AUTOSAR XML (schema 4-2-2)
package /ComponentTypes
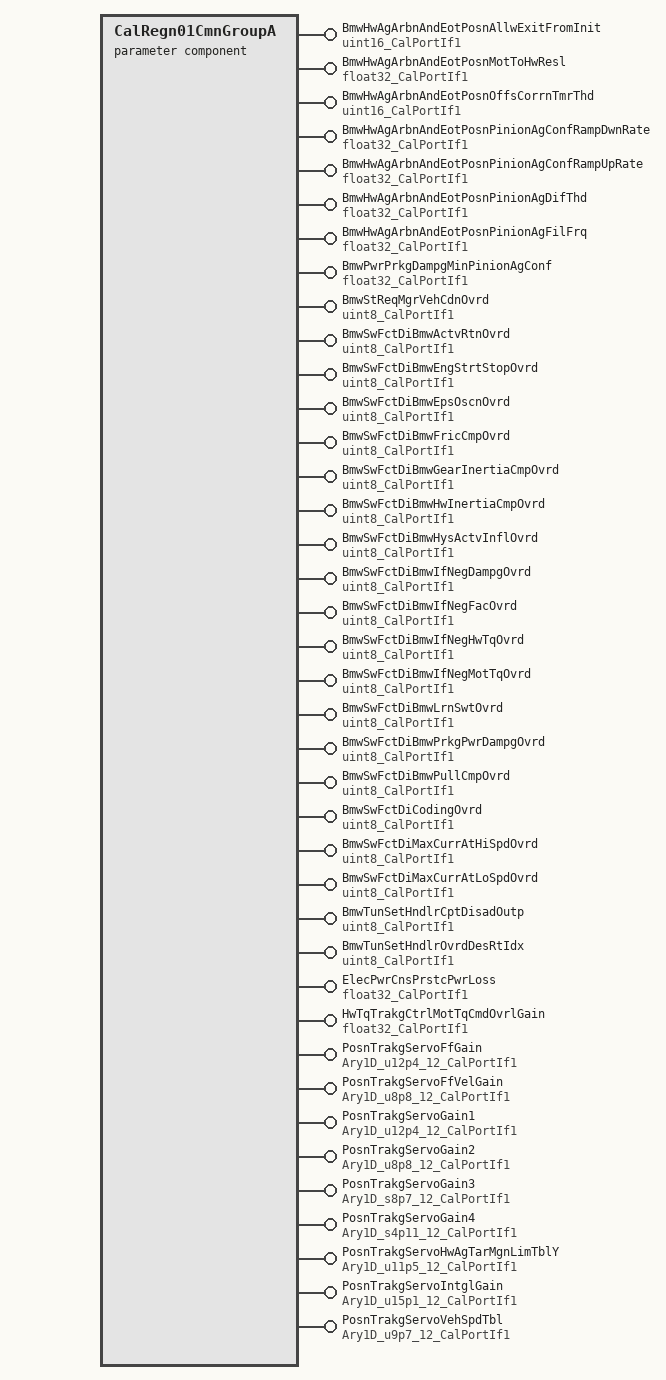
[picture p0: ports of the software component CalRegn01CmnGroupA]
  parameter sw component type CalRegn01CmnGroupA
    39 x provide port:
      BmwHwAgArbnAndEotPosnAllwExitFromInit: parameter-provide-com-spec{init-value=200, parameter=Val}, provided-interface=uint16_CalPortIf1
      BmwHwAgArbnAndEotPosnMotToHwResl: parameter-provide-com-spec{init-value=1, parameter=Val}, provided-interface=float32_CalPortIf1
      BmwHwAgArbnAndEotPosnOffsCorrnTmrThd: parameter-provide-com-spec{init-value=50, parameter=Val}, provided-interface=uint16_CalPortIf1
      BmwHwAgArbnAndEotPosnPinionAgConfRampDwnRate: parameter-provide-com-spec{init-value=1, parameter=Val}, provided-interface=float32_CalPortIf1
      BmwHwAgArbnAndEotPosnPinionAgConfRampUpRate: parameter-provide-com-spec{init-value=0.2, parameter=Val}, provided-interface=float32_CalPortIf1
      BmwHwAgArbnAndEotPosnPinionAgDifThd: parameter-provide-com-spec{init-value=7.5, parameter=Val}, provided-interface=float32_CalPortIf1
      BmwHwAgArbnAndEotPosnPinionAgFilFrq: parameter-provide-com-spec{init-value=10, parameter=Val}, provided-interface=float32_CalPortIf1
      BmwPwrPrkgDampgMinPinionAgConf: parameter-provide-com-spec{init-value=1, parameter=Val}, provided-interface=float32_CalPortIf1
      BmwStReqMgrVehCdnOvrd: parameter-provide-com-spec{init-value=15, parameter=Val}, provided-interface=uint8_CalPortIf1
      BmwSwFctDiBmwActvRtnOvrd: parameter-provide-com-spec{init-value=255, parameter=Val}, provided-interface=uint8_CalPortIf1
      BmwSwFctDiBmwEngStrtStopOvrd: parameter-provide-com-spec{init-value=255, parameter=Val}, provided-interface=uint8_CalPortIf1
      BmwSwFctDiBmwEpsOscnOvrd: parameter-provide-com-spec{init-value=255, parameter=Val}, provided-interface=uint8_CalPortIf1
      BmwSwFctDiBmwFricCmpOvrd: parameter-provide-com-spec{init-value=255, parameter=Val}, provided-interface=uint8_CalPortIf1
      BmwSwFctDiBmwGearInertiaCmpOvrd: parameter-provide-com-spec{init-value=255, parameter=Val}, provided-interface=uint8_CalPortIf1
      BmwSwFctDiBmwHwInertiaCmpOvrd: parameter-provide-com-spec{init-value=255, parameter=Val}, provided-interface=uint8_CalPortIf1
      BmwSwFctDiBmwHysActvInflOvrd: parameter-provide-com-spec{init-value=255, parameter=Val}, provided-interface=uint8_CalPortIf1
      BmwSwFctDiBmwIfNegDampgOvrd: parameter-provide-com-spec{init-value=255, parameter=Val}, provided-interface=uint8_CalPortIf1
      BmwSwFctDiBmwIfNegFacOvrd: parameter-provide-com-spec{init-value=255, parameter=Val}, provided-interface=uint8_CalPortIf1
      BmwSwFctDiBmwIfNegHwTqOvrd: parameter-provide-com-spec{init-value=255, parameter=Val}, provided-interface=uint8_CalPortIf1
      BmwSwFctDiBmwIfNegMotTqOvrd: parameter-provide-com-spec{init-value=255, parameter=Val}, provided-interface=uint8_CalPortIf1
      BmwSwFctDiBmwLrnSwtOvrd: parameter-provide-com-spec{init-value=255, parameter=Val}, provided-interface=uint8_CalPortIf1
      BmwSwFctDiBmwPrkgPwrDampgOvrd: parameter-provide-com-spec{init-value=255, parameter=Val}, provided-interface=uint8_CalPortIf1
      BmwSwFctDiBmwPullCmpOvrd: parameter-provide-com-spec{init-value=255, parameter=Val}, provided-interface=uint8_CalPortIf1
      BmwSwFctDiCodingOvrd: parameter-provide-com-spec{init-value=255, parameter=Val}, provided-interface=uint8_CalPortIf1
      BmwSwFctDiMaxCurrAtHiSpdOvrd: parameter-provide-com-spec{init-value=0, parameter=Val}, provided-interface=uint8_CalPortIf1
      BmwSwFctDiMaxCurrAtLoSpdOvrd: parameter-provide-com-spec{init-value=0, parameter=Val}, provided-interface=uint8_CalPortIf1
      BmwTunSetHndlrCptDisadOutp: parameter-provide-com-spec{init-value=0, parameter=Val}, provided-interface=uint8_CalPortIf1
      BmwTunSetHndlrOvrdDesRtIdx: parameter-provide-com-spec{init-value=5, parameter=Val}, provided-interface=uint8_CalPortIf1
      ElecPwrCnsPrstcPwrLoss: parameter-provide-com-spec{init-value=10, parameter=Val}, provided-interface=float32_CalPortIf1
      HwTqTrakgCtrlMotTqCmdOvrlGain: parameter-provide-com-spec{init-value=0, parameter=Val}, provided-interface=float32_CalPortIf1
      PosnTrakgServoFfGain: parameter-provide-com-spec{init-value=12 x 0, parameter=Ary1D}, provided-interface=Ary1D_u12p4_12_CalPortIf1
      PosnTrakgServoFfVelGain: parameter-provide-com-spec{init-value=12 x 0, parameter=Ary1D}, provided-interface=Ary1D_u8p8_12_CalPortIf1
      PosnTrakgServoGain1: parameter-provide-com-spec{init-value=12 x 16261, parameter=Ary1D}, provided-interface=Ary1D_u12p4_12_CalPortIf1
      PosnTrakgServoGain2: parameter-provide-com-spec{init-value=12 x 5780, parameter=Ary1D}, provided-interface=Ary1D_u8p8_12_CalPortIf1
      PosnTrakgServoGain3: parameter-provide-com-spec{init-value=12 x -326, parameter=Ary1D}, provided-interface=Ary1D_s8p7_12_CalPortIf1
      PosnTrakgServoGain4: parameter-provide-com-spec{init-value=12 x 222, parameter=Ary1D}, provided-interface=Ary1D_s4p11_12_CalPortIf1
      PosnTrakgServoHwAgTarMgnLimTblY: parameter-provide-com-spec{init-value=[4480, 14400, 11520, 5760, 5760, 5760, 5760, 5760, 5760, 5760, 5760, 5760], parameter=Ary1D}, provided-interface=Ary1D_u11p5_12_CalPortIf1
      PosnTrakgServoIntglGain: parameter-provide-com-spec{init-value=12 x 23464, parameter=Ary1D}, provided-interface=Ary1D_u15p1_12_CalPortIf1
      PosnTrakgServoVehSpdTbl: parameter-provide-com-spec{init-value=[0, 1280, 2560, 3840, 5120, 6400, 7680, 8960, 10240, 11520, 12800, 14080], parameter=Ary1D}, provided-interface=Ary1D_u9p7_12_CalPortIf1
